# PLL0_CFG register map
Vendor: Texas Instruments
Peripheral module from a debugger description file (folder J721S2).
Registers are 32-bit, read-write, reset values left out (the file's numbers can be read two ways) unless marked. A register's access mark holds for its fields unless they carry their own. Offsets are as the file gives them; lines under a group give offsets from that group; [hi:lo] are bit positions; {n}, {i} and the like mark numbered series; 'fields as' and 'values as' point back to an identical list; <NAME> marks a mode.

## PLL0_CFG
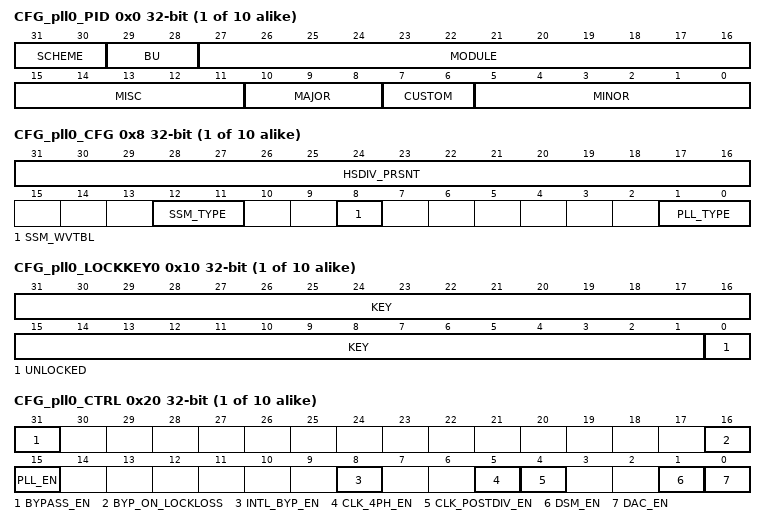
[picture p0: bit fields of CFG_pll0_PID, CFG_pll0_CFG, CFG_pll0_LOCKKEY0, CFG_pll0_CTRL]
{0x0+0x1000*i} CFG_pll{i}_PID ro (i=0..9)
  [31:30] SCHEME — PID follows new scheme
  [29:28] BU — Business Unit - Processors
  [27:16] MODULE — Module functional identifier
  [15:11] MISC — Misc revision number
  [10:8] MAJOR — Major revision number
  [7:6] CUSTOM — custom revision number
  [5:0] MINOR — Minor revision number
{0x8+0x1000*i} CFG_pll{i}_CFG ro (i=0..9)
  [31:16] HSDIV_PRSNT — High Speed Divider Presence Each bit Indicates the presence of High Speed dividers 0-15. By definition HSDIV[4:0] are connected the PLL FOUTVCO output clock and HSDIV[15:5] are connected to the PLL FOUTPOSTDIV output clock
  [12:11] SSM_TYPE — Spread spectrum module presence Field values (Others are reserved): 2'b00 - SSM is not present 2'b01 - SSM is present 2'b10 - Reserved 2'b11 - Reserved
  [8] SSM_WVTBL — Spread spectrum wave table presence 1'b0 - SSM Wave table is not present 1'b1 - SSM Wave table is present
  [1:0] PLL_TYPE — Indicates PLL type Field values (Others are reserved): 2'b00 - Fractional PLL 2'b01 - FractionalF PLL 2'b10 - De-Skew PLL
{0x10+0x1000*i} CFG_pll{i}_LOCKKEY0 access per field (i=0..9)
  [31:1] KEY rw — Write the kick0 unlock value followed by the kick1 unlock value to unlock the write-protected Partition{i} registers
  [0] UNLOCKED ro — Unlock status. When set, indicates that the proper unlock sequence has been performed and the partition is unlocked for writing.
{0x14+0x1000*i} CFG_pll{i}_LOCKKEY1 (i=0..9)
  [31:0] LOCKKEY1_VAL — Write the kick1 unlock value after the kick0 unlock value to unlock the write-protected Partition{i} registers
{0x20+0x1000*i} CFG_pll{i}_CTRL (i=0..9)
  [31] BYPASS_EN — Bypass enable. This controls the glitch-free bypass mux. The bypass_en bit should be set prior tomaking any changes to the PLL settings. 1'b0 - Synchronously select PLL and associated HSDIV clock outputs 1'b1 - Synchronously select the reference clock for all PLL and HSDIV clock outputs
  [16] BYP_ON_LOCKLOSS — Bypass on loss of PLL lock. This bit controls the PLL bypass mux to automatically switch the clock source to the reference clock when the PLL losses lock. 1'b0 - Do not automatically switch to ref clock source on PLL lock loss 1'b1 - Switch to ref clock source when PLL losses lock
  [15] PLL_EN — PLL enable 1'b0 - PLL is disabled 1'b1 - PLL is enabled
  [8] INTL_BYP_EN — PLL internal bypass enable. This is an asynchronous mux which can produce glitches on the outputclocks during switching. 1'b0 - Output clocks are derived from the VCO clock 1'b1 - Output clocks are derived from the FREF reference clock
  [5] CLK_4PH_EN — Enable 4-phase clock generator. This bit is ignored if clk_postdiv_en=0 1'b0 - 4-phase dividers disabled. FOUT1PHx and FOUTn clocks are held low. 1'b1 - 4-phase dividers enabled. FOUT1PH0/90/180/270 and FOUT2, FOUT3, FOUT4 clocks are enabled.
  [4] CLK_POSTDIV_EN — Post divide CLK enable 1'b0 - Post divide powered down. FOUTPOSTDIV and all auxiliary PLL clocks (4-ohase and synchronous divided clocks) are held low 1'b1 - Post divide enabled. FOUTPOSTDIV, 4-phase and synchronous clocks are enabled.
  [1] DSM_EN — Delta-Sigma modulator enable 1'b0 - Delta-Sigma modulator is disabled (use integer divide mode) 1'b1 - Delta-Sigma modulator is enabled (use fractional divide mode)
  [0] DAC_EN — Enable fractional noise canceling DAC This bit has no function (DAC is always disabled) in integer divide mode (when dsm_en=0) 1'b0 - Fractional NC DAC is disabled (for Test modes only) 1'b1 - Fractional NC DAC is enabled (ignored in integer divide mode)
{0x24+0x1000*i} CFG_pll{i}_STAT ro (i=0..9)
  [0] LOCK — PLL lock status. Software should wait for lock to be asserted before clearing the PLL_CTRL_bypass_en bit 1'b0 - PLL is not locked 1'b1 - PLL is locked
{0x30+0x1000*i} CFG_pll{i}_FREQ_CTRL0 (i=0..9)
  [11:0] FB_DIV_INT — PLL feedback divider (integer portion) In Integer mode values of 16 - 3200 (dec) are supported. In Fractional mode values of 20 to 320 are supported. 12'h010 - Divide by 16 12'h011 - Divide by 17 : 12'h140 - Divide by 320 : 12'hC80 - Divide by 3200 12'hC81 - 12'hFFF - Not supported
{0x34+0x1000*i} CFG_pll{i}_FREQ_CTRL1 (i=0..9)
  [23:0] FB_DIV_FRAC — PLL feedback divider (fractional portion) Supports values of 0 to 0.999999940395. The total feedback divide value is (fb_div_int + fb_div_frac / (2^24)) 24'h000000 - 0 24'h000001 - .000000059605 (1/(2^24)) 24'h000002 - .000000119209 (2/(2^24)) : 24'h800000 - .500000000000 : 24'hFFFFFF - .999999940395 (1677215/(2^24))
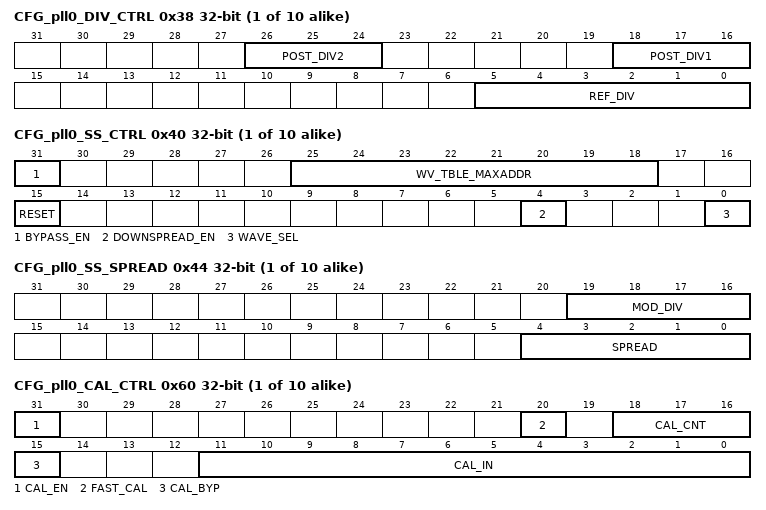
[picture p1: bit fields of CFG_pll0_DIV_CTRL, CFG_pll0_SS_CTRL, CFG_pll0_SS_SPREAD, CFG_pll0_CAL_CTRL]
{0x38+0x1000*i} CFG_pll{i}_DIV_CTRL (i=0..9)
  [26:24] POST_DIV2 — Secondary post divider. Supports values of 1-7
  [18:16] POST_DIV1 — Primary post divider. To ensure correct operation, post_div1 must always be programmed to a value equal to or greater that post_div2. Supports values of 1-7i Field values (Others are reserved): 3'b000 - Reserved (do not use) 3'b001 - Divide by 1 3'b010 - Divide by 2 3'b011 - Divide by 3 3'b100 - Divide by 4 3'b101 - Divide by 5 3'b110 - Divide by 6 3'b111 - Divide by 7
  [5:0] REF_DIV — Reference clock pre-divider. Supports values of 1-63 6'b000000 - Reserved /(do not use/) 6'b000001 - Divide by 1 6'b000010 - Divide by 2 : 6'b111111 - Divide by 63
{0x40+0x1000*i} CFG_pll{i}_SS_CTRL (i=0..9)
  [31] BYPASS_EN — Bypass the SS modulator. 1'b0 - Spread spectrum modulation is enabled 1'b1 - SSMOD is bypassed. No modulation of PLL frequency
  [25:18] WV_TBLE_MAXADDR — Wave table max address. Indicates the maximum number of address bits used to access the external wave table. These bits are not used if PLL_CFG_ssm_wvtbl = 0
  [15] RESET — SSM reset. When set to 1 the SSM modulator is in reset
  [4] DOWNSPREAD_EN — Selects center spread or down spread clock variance 1'b0 - Center spread 1'b1 - Down spread
  [0] WAVE_SEL — Wave pattern select External wave table should only be selected if PLL_CFG_ssm_wvtbl = 1 Field values (Others are reserved): 1'b0 - Use 128 point triangle wave table 1'b1 - Use external wave table
{0x44+0x1000*i} CFG_pll{i}_SS_SPREAD (i=0..9)
  [19:16] MOD_DIV — Input clock divider. This divider sets the modulation frequency. Supports divide values of 1-63
  [4:0] SPREAD — Sets the spread modulation depth. The depth is spread*0.1% 5'b00000 - Reserved (don't use) 5'b00001 - 0.1% 5'b00010 - 0.2% : 5'b10000 - 1.6% : 5'b11111 - 3.1%
{0x60+0x1000*i} CFG_pll{i}_CAL_CTRL (i=0..9)
  [31] CAL_EN — Calibration enable to actively adjust for input skew 1'b0 - Disabled. Static phase offset determined by analog matching only 1'b1 - Enabled. Static phase offset adjusted by phase sensing at input
  [20] FAST_CAL — Fast calibration enabled 1'b0 - Normal operation 1'b1 - Used for initial calibration if initial value is not already known
  [18:16] CAL_CNT — Calibration loop programmable counter. Selects the number of PFD edges to wait after each calibration step defined by 2**cal_cnt
  [15] CAL_BYP — Calibration bypass 1'b0 - Use the calibration output to set the phase correction 1'b1 - Use the cal_in input value to set the phase correction
  [11:0] CAL_IN — Calibration input When cal_byp is 1'b0, this represents the initial condition for calibration. When cal_byp is 1'b1, this is the override value for calibration. Value is a signed integer with positive values delaying the faster path reset and negative values delaying the slower path reset.
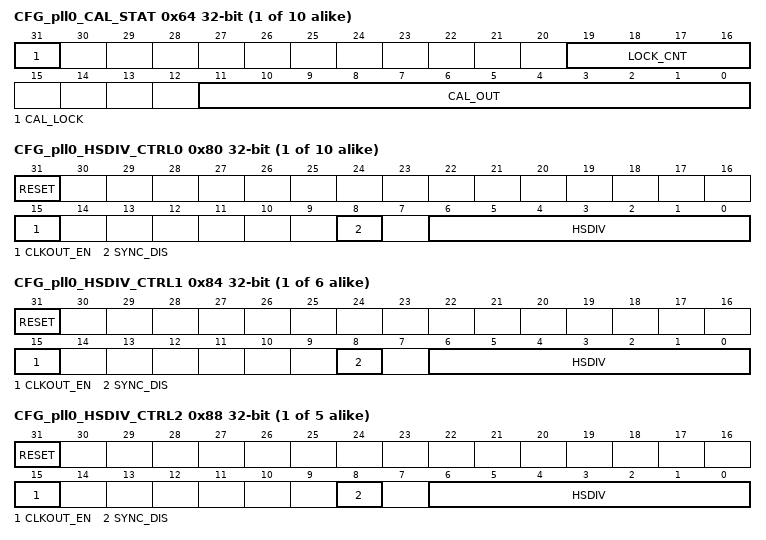
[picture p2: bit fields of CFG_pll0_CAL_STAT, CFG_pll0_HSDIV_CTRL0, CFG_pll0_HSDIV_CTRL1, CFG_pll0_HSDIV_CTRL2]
{0x64+0x1000*i} CFG_pll{i}_CAL_STAT ro (i=0..9)
  [31] CAL_LOCK — Reserved for future use
  [19:16] LOCK_CNT — Reserved for future use
  [11:0] CAL_OUT — Output of the calibration block if cal_byp = 1'b0. If cal_byp = 1'b1 it is a buffer version of cal_in[11:0]. Can be used to read the phase calibration state to for later use as an override value to bypass skew calibration
{0x80+0x1000*i} CFG_pll{i}_HSDIV_CTRL0 (i=0..9)
  [31] RESET — SSM reset. When set to 1 the SSM modulator is in resetl
  [15] CLKOUT_EN — CLKOUT1 enable 1'b0 - Synchronously disable CLKOUT1 1'b1 - Synchronously enable CLKOUT1
  [8] SYNC_DIS — Disable divider synchronization logic 0 - Changes to DIV value synchronized to prevent glitches 1 - Changes are asynchronous
  [6:0] HSDIV — CLKOUT0 divider value (HSDIV1+1) Allowed values are 0-127
{0x84+0x1000*i} CFG_pll{i}_HSDIV_CTRL1 (i=0..5)
  fields as CFG_pll0_HSDIV_CTRL0
{0x88+0x1000*i} CFG_pll{i}_HSDIV_CTRL2 (i=0..4)
  fields as CFG_pll0_HSDIV_CTRL0
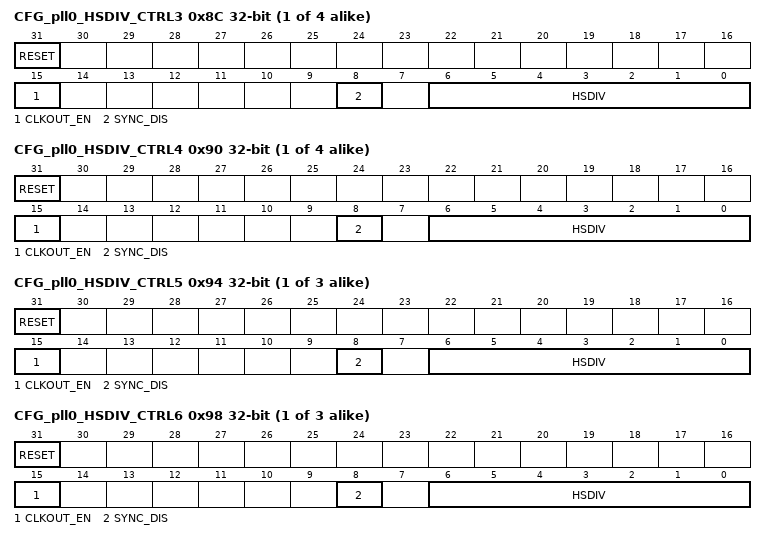
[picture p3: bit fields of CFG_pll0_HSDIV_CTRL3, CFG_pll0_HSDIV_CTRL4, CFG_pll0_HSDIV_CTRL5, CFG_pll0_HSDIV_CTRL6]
{0x8C+0x1000*i} CFG_pll{i}_HSDIV_CTRL3 (i=0..3)
  fields as CFG_pll0_HSDIV_CTRL0
{0x90+0x1000*i} CFG_pll{i}_HSDIV_CTRL4 (i=0..3)
  fields as CFG_pll0_HSDIV_CTRL0
{0x94+0x1000*i} CFG_pll{i}_HSDIV_CTRL5 (i=0..2)
  fields as CFG_pll0_HSDIV_CTRL0
{0x98+0x1000*i} CFG_pll{i}_HSDIV_CTRL6 (i=0..2)
  fields as CFG_pll0_HSDIV_CTRL0
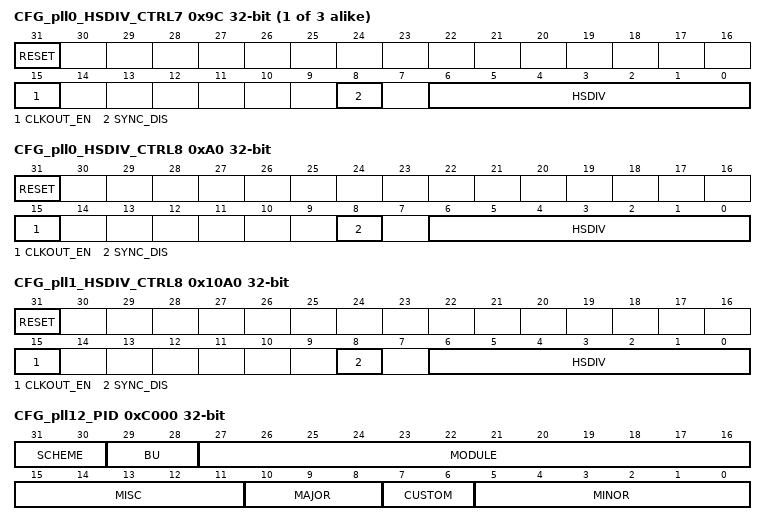
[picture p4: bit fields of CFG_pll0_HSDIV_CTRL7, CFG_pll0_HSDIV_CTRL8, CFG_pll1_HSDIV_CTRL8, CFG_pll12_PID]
{0x9C+0x1000*i} CFG_pll{i}_HSDIV_CTRL7 (i=0..2)
  fields as CFG_pll0_HSDIV_CTRL0
0xA0 CFG_pll0_HSDIV_CTRL8
  fields as CFG_pll0_HSDIV_CTRL0
0x10A0 CFG_pll1_HSDIV_CTRL8
  fields as CFG_pll0_HSDIV_CTRL0
0xC000 CFG_pll12_PID ro
  fields as CFG_pll0_PID
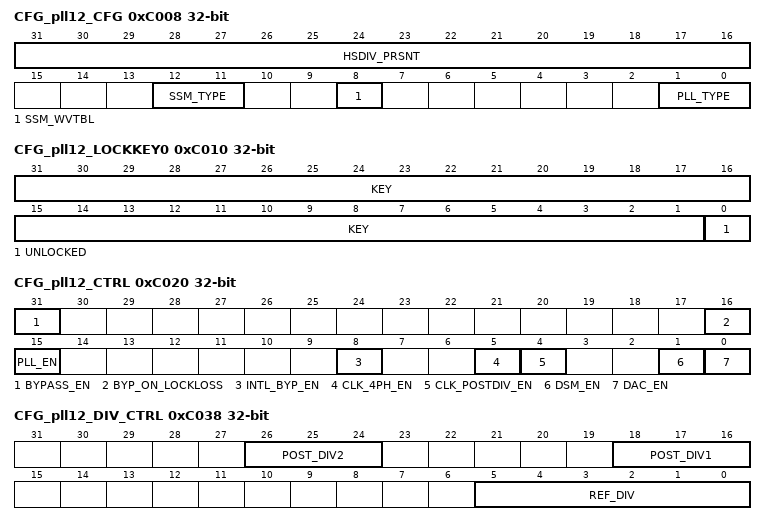
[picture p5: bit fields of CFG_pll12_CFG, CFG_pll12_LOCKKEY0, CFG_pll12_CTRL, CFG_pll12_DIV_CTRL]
0xC008 CFG_pll12_CFG ro
  fields as CFG_pll0_CFG
0xC010 CFG_pll12_LOCKKEY0 access per field
  [31:1] KEY rw — Write the kick0 unlock value followed by the kick1 unlock value to unlock the write-protected Partition12 registers
  [0] UNLOCKED ro — Unlock status. When set, indicates that the proper unlock sequence has been performed and the partition is unlocked for writing.
0xC014 CFG_pll12_LOCKKEY1
  [31:0] LOCKKEY1_VAL — Write the kick1 unlock value after the kick0 unlock value to unlock the write-protected Partition12 registers
0xC020 CFG_pll12_CTRL
  fields as CFG_pll0_CTRL
0xC024 CFG_pll12_STAT ro
  fields as CFG_pll0_STAT
0xC030 CFG_pll12_FREQ_CTRL0
  fields as CFG_pll0_FREQ_CTRL0
0xC034 CFG_pll12_FREQ_CTRL1
  fields as CFG_pll0_FREQ_CTRL1
0xC038 CFG_pll12_DIV_CTRL
  fields as CFG_pll0_DIV_CTRL
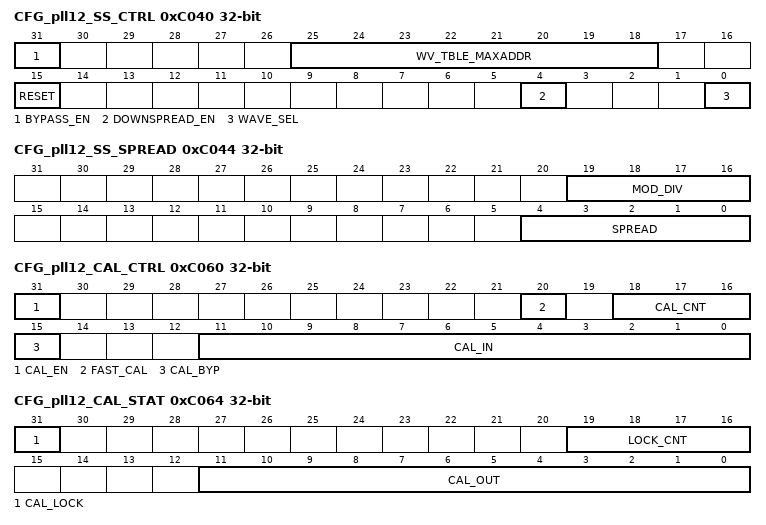
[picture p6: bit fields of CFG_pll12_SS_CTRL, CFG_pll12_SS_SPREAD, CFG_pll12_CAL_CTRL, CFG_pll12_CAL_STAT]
0xC040 CFG_pll12_SS_CTRL
  fields as CFG_pll0_SS_CTRL
0xC044 CFG_pll12_SS_SPREAD
  fields as CFG_pll0_SS_SPREAD
0xC060 CFG_pll12_CAL_CTRL
  fields as CFG_pll0_CAL_CTRL
0xC064 CFG_pll12_CAL_STAT ro
  fields as CFG_pll0_CAL_STAT
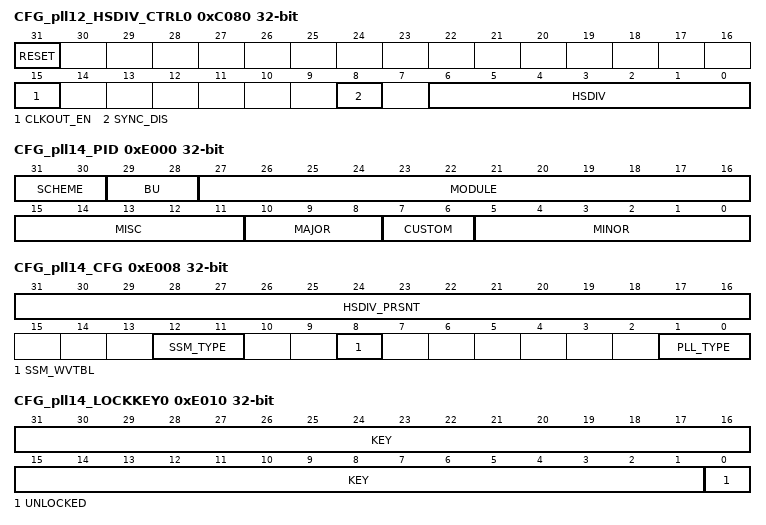
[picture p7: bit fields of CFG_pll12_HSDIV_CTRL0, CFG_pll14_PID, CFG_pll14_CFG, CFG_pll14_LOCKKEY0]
0xC080 CFG_pll12_HSDIV_CTRL0
  fields as CFG_pll0_HSDIV_CTRL0
0xE000 CFG_pll14_PID ro
  fields as CFG_pll0_PID
0xE008 CFG_pll14_CFG ro
  fields as CFG_pll0_CFG
0xE010 CFG_pll14_LOCKKEY0 access per field
  [31:1] KEY rw — Write the kick0 unlock value followed by the kick1 unlock value to unlock the write-protected Partition14 registers
  [0] UNLOCKED ro — Unlock status. When set, indicates that the proper unlock sequence has been performed and the partition is unlocked for writing.
0xE014 CFG_pll14_LOCKKEY1
  [31:0] LOCKKEY1_VAL — Write the kick1 unlock value after the kick0 unlock value to unlock the write-protected Partition14 registers
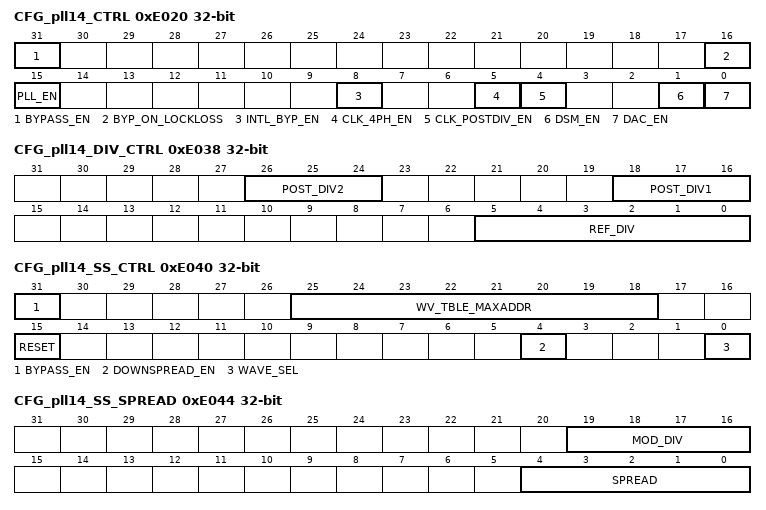
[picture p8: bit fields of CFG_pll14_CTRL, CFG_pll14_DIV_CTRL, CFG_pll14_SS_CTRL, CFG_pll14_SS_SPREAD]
0xE020 CFG_pll14_CTRL
  fields as CFG_pll0_CTRL
0xE024 CFG_pll14_STAT ro
  fields as CFG_pll0_STAT
0xE030 CFG_pll14_FREQ_CTRL0
  fields as CFG_pll0_FREQ_CTRL0
0xE034 CFG_pll14_FREQ_CTRL1
  fields as CFG_pll0_FREQ_CTRL1
0xE038 CFG_pll14_DIV_CTRL
  fields as CFG_pll0_DIV_CTRL
0xE040 CFG_pll14_SS_CTRL
  fields as CFG_pll0_SS_CTRL
0xE044 CFG_pll14_SS_SPREAD
  fields as CFG_pll0_SS_SPREAD
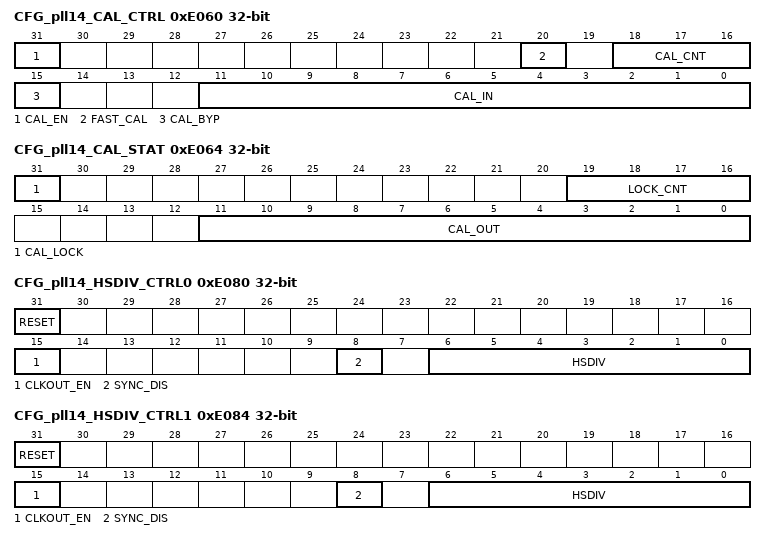
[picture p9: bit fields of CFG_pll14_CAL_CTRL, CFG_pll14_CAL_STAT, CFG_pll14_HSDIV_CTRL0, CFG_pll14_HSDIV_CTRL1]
0xE060 CFG_pll14_CAL_CTRL
  fields as CFG_pll0_CAL_CTRL
0xE064 CFG_pll14_CAL_STAT ro
  fields as CFG_pll0_CAL_STAT
0xE080 CFG_pll14_HSDIV_CTRL0
  fields as CFG_pll0_HSDIV_CTRL0
0xE084 CFG_pll14_HSDIV_CTRL1
  fields as CFG_pll0_HSDIV_CTRL0
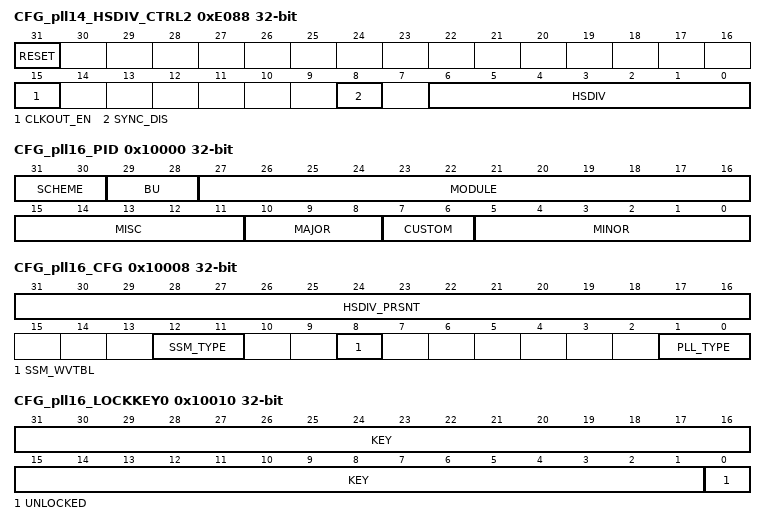
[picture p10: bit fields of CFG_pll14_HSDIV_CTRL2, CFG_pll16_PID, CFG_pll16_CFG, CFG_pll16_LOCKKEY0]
0xE088 CFG_pll14_HSDIV_CTRL2
  fields as CFG_pll0_HSDIV_CTRL0
0x10000 CFG_pll16_PID ro
  fields as CFG_pll0_PID
0x10008 CFG_pll16_CFG ro
  fields as CFG_pll0_CFG
0x10010 CFG_pll16_LOCKKEY0 access per field
  [31:1] KEY rw — Write the kick0 unlock value followed by the kick1 unlock value to unlock the write-protected Partition16 registers
  [0] UNLOCKED ro — Unlock status. When set, indicates that the proper unlock sequence has been performed and the partition is unlocked for writing.
0x10014 CFG_pll16_LOCKKEY1
  [31:0] LOCKKEY1_VAL — Write the kick1 unlock value after the kick0 unlock value to unlock the write-protected Partition16 registers
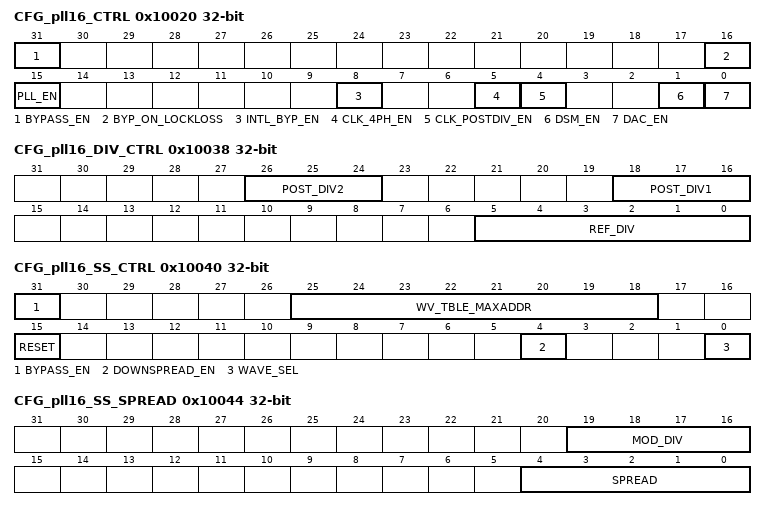
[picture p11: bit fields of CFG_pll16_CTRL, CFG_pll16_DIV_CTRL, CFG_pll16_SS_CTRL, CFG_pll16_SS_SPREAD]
0x10020 CFG_pll16_CTRL
  fields as CFG_pll0_CTRL
0x10024 CFG_pll16_STAT ro
  fields as CFG_pll0_STAT
0x10030 CFG_pll16_FREQ_CTRL0
  fields as CFG_pll0_FREQ_CTRL0
0x10034 CFG_pll16_FREQ_CTRL1
  fields as CFG_pll0_FREQ_CTRL1
0x10038 CFG_pll16_DIV_CTRL
  fields as CFG_pll0_DIV_CTRL
0x10040 CFG_pll16_SS_CTRL
  fields as CFG_pll0_SS_CTRL
0x10044 CFG_pll16_SS_SPREAD
  fields as CFG_pll0_SS_SPREAD
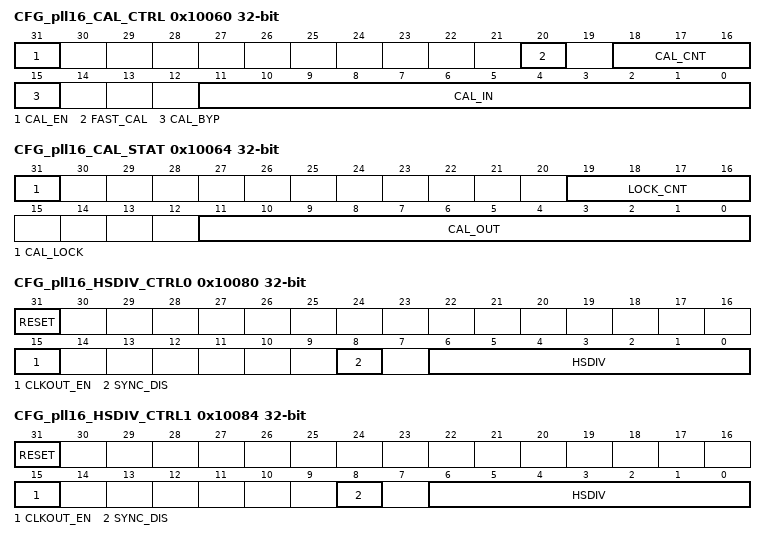
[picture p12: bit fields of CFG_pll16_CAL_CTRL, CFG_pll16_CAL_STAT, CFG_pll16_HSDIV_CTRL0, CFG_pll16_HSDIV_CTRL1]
0x10060 CFG_pll16_CAL_CTRL
  fields as CFG_pll0_CAL_CTRL
0x10064 CFG_pll16_CAL_STAT ro
  fields as CFG_pll0_CAL_STAT
0x10080 CFG_pll16_HSDIV_CTRL0
  fields as CFG_pll0_HSDIV_CTRL0
0x10084 CFG_pll16_HSDIV_CTRL1
  fields as CFG_pll0_HSDIV_CTRL0
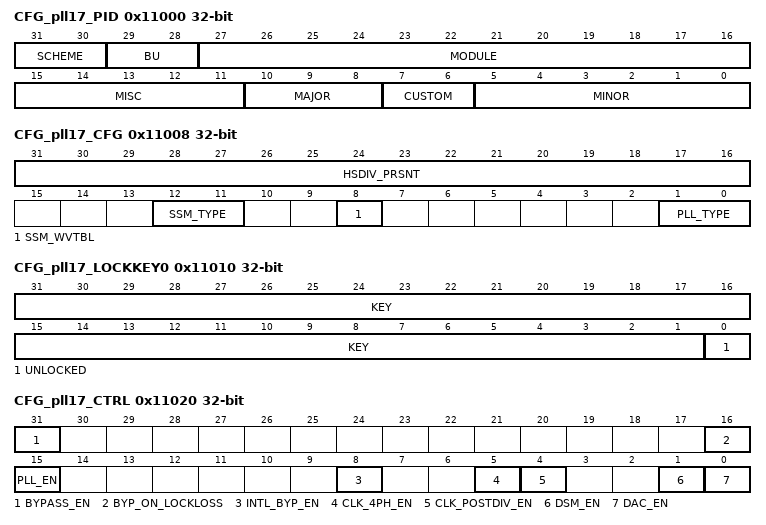
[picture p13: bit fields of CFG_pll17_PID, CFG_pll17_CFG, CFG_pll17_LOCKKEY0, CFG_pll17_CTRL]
0x11000 CFG_pll17_PID ro
  fields as CFG_pll0_PID
0x11008 CFG_pll17_CFG ro
  fields as CFG_pll0_CFG
0x11010 CFG_pll17_LOCKKEY0 access per field
  [31:1] KEY rw — Write the kick0 unlock value followed by the kick1 unlock value to unlock the write-protected Partition17 registers
  [0] UNLOCKED ro — Unlock status. When set, indicates that the proper unlock sequence has been performed and the partition is unlocked for writing.
0x11014 CFG_pll17_LOCKKEY1
  [31:0] LOCKKEY1_VAL — Write the kick1 unlock value after the kick0 unlock value to unlock the write-protected Partition17 registers
0x11020 CFG_pll17_CTRL
  fields as CFG_pll0_CTRL
0x11024 CFG_pll17_STAT ro
  fields as CFG_pll0_STAT
0x11030 CFG_pll17_FREQ_CTRL0
  fields as CFG_pll0_FREQ_CTRL0
0x11034 CFG_pll17_FREQ_CTRL1
  fields as CFG_pll0_FREQ_CTRL1
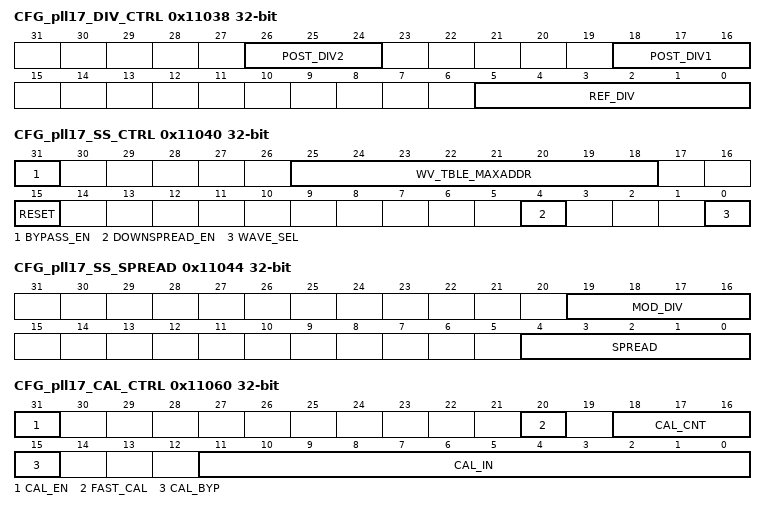
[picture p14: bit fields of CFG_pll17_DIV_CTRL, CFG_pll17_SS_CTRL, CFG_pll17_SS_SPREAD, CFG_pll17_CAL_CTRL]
0x11038 CFG_pll17_DIV_CTRL
  fields as CFG_pll0_DIV_CTRL
0x11040 CFG_pll17_SS_CTRL
  fields as CFG_pll0_SS_CTRL
0x11044 CFG_pll17_SS_SPREAD
  fields as CFG_pll0_SS_SPREAD
0x11060 CFG_pll17_CAL_CTRL
  fields as CFG_pll0_CAL_CTRL
0x11064 CFG_pll17_CAL_STAT ro
  fields as CFG_pll0_CAL_STAT
0x11080 CFG_pll17_HSDIV_CTRL0
  fields as CFG_pll0_HSDIV_CTRL0
0x11084 CFG_pll17_HSDIV_CTRL1
  fields as CFG_pll0_HSDIV_CTRL0
0x13000 CFG_pll19_PID ro
  fields as CFG_pll0_PID
0x13008 CFG_pll19_CFG ro
  fields as CFG_pll0_CFG
0x13010 CFG_pll19_LOCKKEY0 access per field
  [31:1] KEY rw — Write the kick0 unlock value followed by the kick1 unlock value to unlock the write-protected Partition19 registers
  [0] UNLOCKED ro — Unlock status. When set, indicates that the proper unlock sequence has been performed and the partition is unlocked for writing.
0x13014 CFG_pll19_LOCKKEY1
  [31:0] LOCKKEY1_VAL — Write the kick1 unlock value after the kick0 unlock value to unlock the write-protected Partition19 registers
0x13020 CFG_pll19_CTRL
  fields as CFG_pll0_CTRL
0x13024 CFG_pll19_STAT ro
  fields as CFG_pll0_STAT
0x13030 CFG_pll19_FREQ_CTRL0
  fields as CFG_pll0_FREQ_CTRL0
0x13034 CFG_pll19_FREQ_CTRL1
  fields as CFG_pll0_FREQ_CTRL1
0x13038 CFG_pll19_DIV_CTRL
  fields as CFG_pll0_DIV_CTRL
0x13040 CFG_pll19_SS_CTRL
  fields as CFG_pll0_SS_CTRL
0x13044 CFG_pll19_SS_SPREAD
  fields as CFG_pll0_SS_SPREAD
0x13060 CFG_pll19_CAL_CTRL
  fields as CFG_pll0_CAL_CTRL
0x13064 CFG_pll19_CAL_STAT ro
  fields as CFG_pll0_CAL_STAT
0x13080 CFG_pll19_HSDIV_CTRL0
  fields as CFG_pll0_HSDIV_CTRL0
0x13084 CFG_pll19_HSDIV_CTRL1
  fields as CFG_pll0_HSDIV_CTRL0
{0x0+0x1000*i} CFG_pll{i}_PID ro (i=25..28)
  fields as CFG_pll0_PID
{0x8+0x1000*i} CFG_pll{i}_CFG ro (i=25..28)
  fields as CFG_pll0_CFG
{0x10+0x1000*i} CFG_pll{i}_LOCKKEY0 access per field (i=25..28)
  fields as CFG_pll0_LOCKKEY0
{0x14+0x1000*i} CFG_pll{i}_LOCKKEY1 (i=25..28)
  fields as CFG_pll0_LOCKKEY1
{0x20+0x1000*i} CFG_pll{i}_CTRL (i=25..28)
  fields as CFG_pll0_CTRL
{0x24+0x1000*i} CFG_pll{i}_STAT ro (i=25..28)
  fields as CFG_pll0_STAT
{0x30+0x1000*i} CFG_pll{i}_FREQ_CTRL0 (i=25..28)
  fields as CFG_pll0_FREQ_CTRL0
{0x34+0x1000*i} CFG_pll{i}_FREQ_CTRL1 (i=25..28)
  fields as CFG_pll0_FREQ_CTRL1
{0x38+0x1000*i} CFG_pll{i}_DIV_CTRL (i=25..28)
  fields as CFG_pll0_DIV_CTRL
{0x40+0x1000*i} CFG_pll{i}_SS_CTRL (i=25..28)
  fields as CFG_pll0_SS_CTRL
{0x44+0x1000*i} CFG_pll{i}_SS_SPREAD (i=25..28)
  fields as CFG_pll0_SS_SPREAD
{0x60+0x1000*i} CFG_pll{i}_CAL_CTRL (i=25..28)
  fields as CFG_pll0_CAL_CTRL
{0x64+0x1000*i} CFG_pll{i}_CAL_STAT ro (i=25..28)
  fields as CFG_pll0_CAL_STAT
{0x80+0x1000*i} CFG_pll{i}_HSDIV_CTRL0 (i=25..28)
  fields as CFG_pll0_HSDIV_CTRL0
0x19084 CFG_pll25_HSDIV_CTRL1
  fields as CFG_pll0_HSDIV_CTRL0
